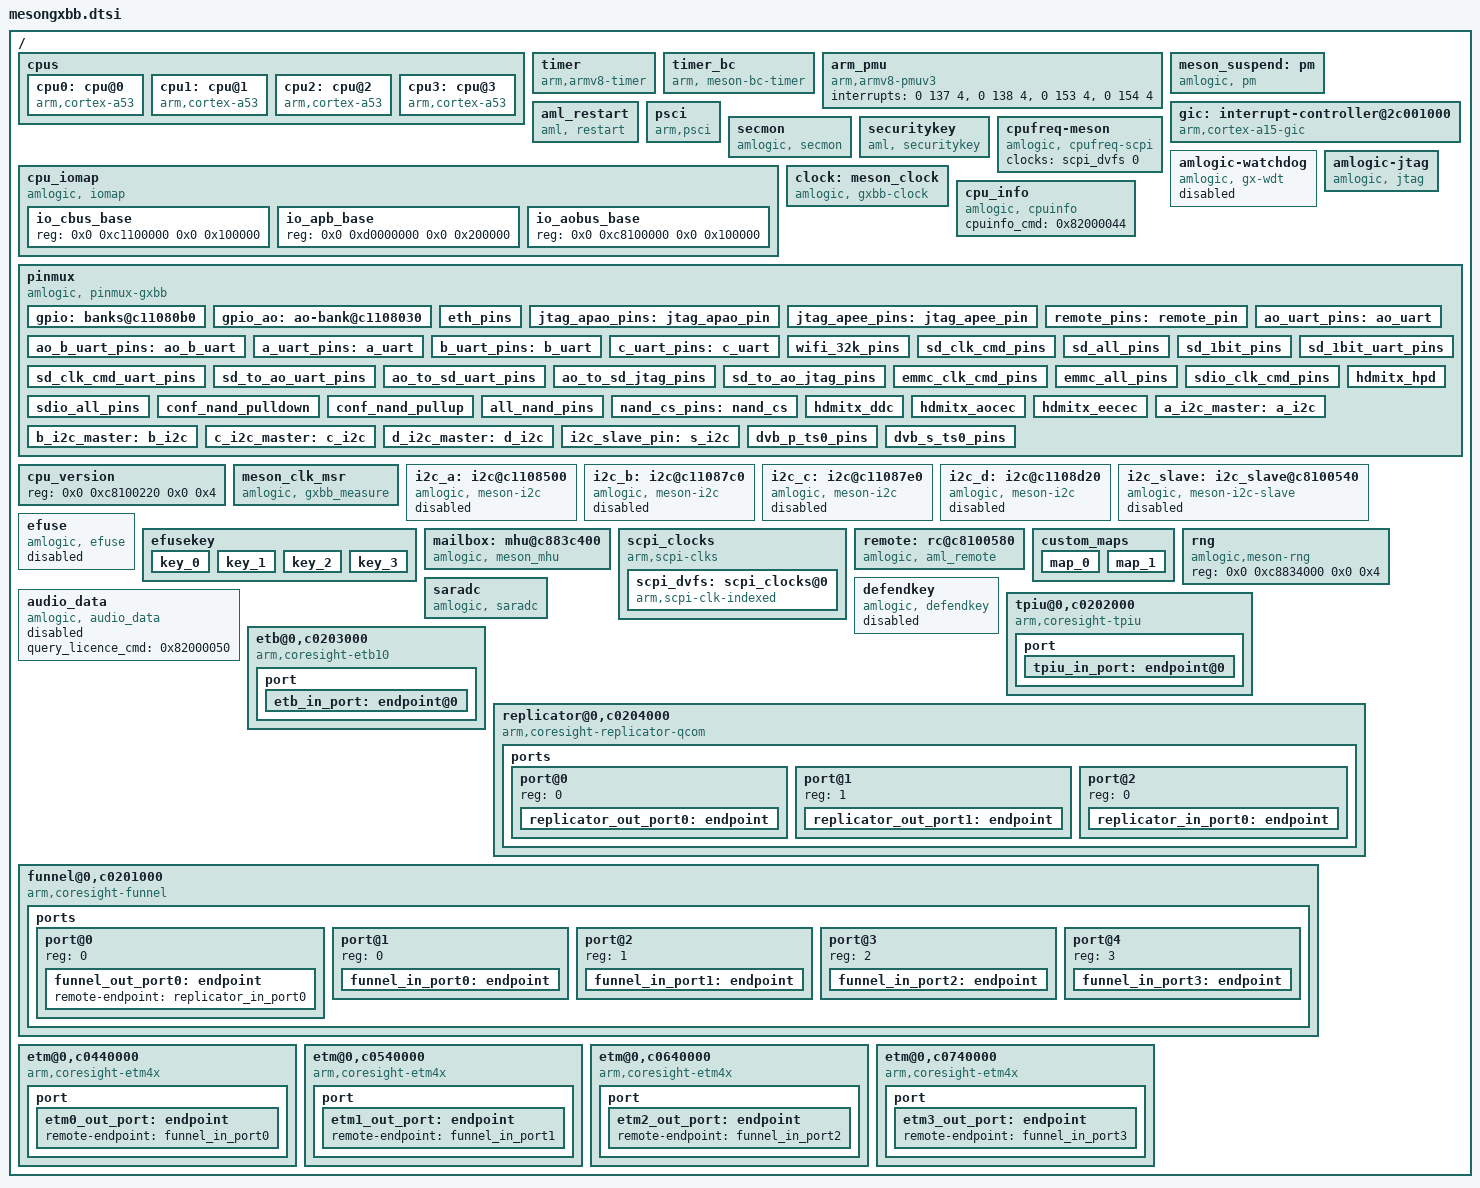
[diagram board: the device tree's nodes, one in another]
#include <dt-bindings/clock/gxbb.h>
#include <dt-bindings/gpio/gxbb.h>
#include <dt-bindings/gpio/gpio.h>
#include <dt-bindings/reset/aml_gxbb.h>
#include <dt-bindings/thermal/thermal.h>
#include <dt-bindings/interrupt-controller/arm-gic.h>
#include <dt-bindings/input/input.h>
#include <dt-bindings/input/meson_rc.h>
#include "mesongxbb-gpu-mali450.dtsi"
/ {
	cpus:cpus {
		#address-cells = <2>;
		#size-cells = <0>;
		#cooling-cells = <2>; /* min followed by max */

		cpu0:cpu@0 {
			device_type = "cpu";
			compatible = "arm,cortex-a53","arm,armv8";
			reg = <0x0 0x0>;
			enable-method = "psci";
		};

		cpu1:cpu@1 {
			device_type = "cpu";
			compatible = "arm,cortex-a53","arm,armv8";
			reg = <0x0 0x1>;
			enable-method = "psci";
		};
		cpu2:cpu@2 {
			device_type = "cpu";
			compatible = "arm,cortex-a53","arm,armv8";
			reg = <0x0 0x2>;
			enable-method = "psci";
		};

		cpu3:cpu@3 {
			device_type = "cpu";
			compatible = "arm,cortex-a53","arm,armv8";
			reg = <0x0 0x3>;
			enable-method = "psci";
		};

	};

	timer {
		compatible = "arm,armv8-timer";
		interrupts = <GIC_PPI 13 0xff01>,
				<GIC_PPI 14 0xff01>,
			        <GIC_PPI 11 0xff01>,
			        <GIC_PPI 10 0xff01>;
	};
	timer_bc {
		compatible = "arm, meson-bc-timer";
		reg=   <0x0 0xc1109990 0x0 0x4 0x0 0xc1109994 0x0 0x4>;
		timer_name = "Meson TimerF";
		clockevent-rating=<300>;
		clockevent-shift=<20>;
		clockevent-features=<0x03>;
		interrupts = <0 60 1>;
		bit_enable=<16>;
		bit_mode=<12>;
		bit_resolution=<0>;
	};
	arm_pmu {
		compatible = "arm,armv8-pmuv3";
		interrupts = <0 137 4>,
			     <0 138 4>,
			     <0 153 4>,
			     <0 154 4>;
	};
	meson_suspend:pm{
	           compatible = "amlogic, pm";
	           device_name = "aml_pm";
	           gxbaby-suspend;
	           reg = <0x0 0xc81000a8 0x0 0x4
				0x0 0xc810023c 0x0 0x4>;
	};

	gic: interrupt-controller@2c001000 {
		compatible = "arm,cortex-a15-gic", "arm,cortex-a9-gic";
		#interrupt-cells = <3>;
		#address-cells = <0>;
		interrupt-controller;
		reg = <0x0 0xc4301000 0 0x1000>,
		      <0x0 0xc4302000 0 0x0100>;
		interrupts = <GIC_PPI 9 0xf04>;
	};

	aml_restart{
		compatible = "aml, restart";
		sys_reset = <0x84000009>;
		sys_poweroff = <0x84000008>;
	};



	psci {
		compatible = "arm,psci";
		method = "smc";
		cpu_suspend = <0xC4000001>;
		cpu_off = <0x84000002>;
		cpu_on = <0xC4000003>;
		migrate = <0xC4000005>;
	};
	secmon {
		compatible = "amlogic, secmon";
		memory-region = <&secmon_reserved>;
		in_base_func = <0x82000020>;
		out_base_func = <0x82000021>;
	};
	securitykey {
		compatible = "aml, securitykey";
		storage_query = <0x82000060>;
		storage_read = <0x82000061>;
		storage_write = <0x82000062>;
		storage_tell = <0x82000063>;
		storage_verify = <0x82000064>;
		storage_status = <0x82000065>;
		storage_list = <0x82000067>;
		storage_remove = <0x82000068>;
		storage_in_func = <0x82000023>;
		storage_out_func = <0x82000024>;
		storage_block_func = <0x82000025>;
		storage_size_func = <0x82000027>;
		storage_set_enctype = <0x8200006A>;
		storage_get_enctype = <0x8200006B>;
		storage_version = <0x8200006C>;
	};
	cpu_iomap{
		compatible = "amlogic, iomap";
		#address-cells=<2>;
		#size-cells=<2>;
		ranges;
		io_cbus_base{
			reg = <0x0 0xc1100000 0x0 0x100000>;
		};
		io_apb_base{
			reg = <0x0 0xd0000000 0x0 0x200000>;
		};
		io_aobus_base{
			reg = <0x0 0xc8100000 0x0 0x100000>;
		};
	};
	cpufreq-meson {
		compatible = "amlogic, cpufreq-scpi";
		status = "okay";
		clocks = <&scpi_dvfs 0>;
		clock-names = "cpu_clk";
        };

	amlogic-watchdog{
		compatible = "amlogic, gx-wdt";
		status = "disable";
		default_timeout=<10>;
		reset_watchdog_method=<1>;//0:sysfs,1:kernel
		reset_watchdog_time=<2>;
		shutdown_timeout=<10>;
		firmware_timeout=<6>;
		suspend_timeout=<6>;
		reg = <0x0 0xc11098d0 0x0 0x10>;
		clocks = <&clock CLK_XTAL>;
	};
	amlogic-jtag {
		compatible = "amlogic, jtag";
		status = "okay";
		pinctrl-names = "jtag_apao_pins", "jtag_apee_pins";
		pinctrl-0 = <&jtag_apao_pins>;
		pinctrl-1 = <&jtag_apee_pins>;
	};
	clock: meson_clock {
		compatible = "amlogic, gxbb-clock";
		reg = <0x0 0xc883c000 0x0 0x1000>,   /* HIU BUS*/
		          <0x0 0xc8100000 0x0 0x1000>;   //AOBUS
		#clock-cells = <1>;
		#reset-cells = <1>;
		sys_max = <1536000000>;
	};
	cpu_info{
		compatible = "amlogic, cpuinfo";
		cpuinfo_cmd = <0x82000044>;
	};
	pinmux: pinmux{
		compatible = "amlogic, pinmux-gxbb";
		dev_name = "pinmux";
		#pinmux-cells=<2>;
		#address-cells = <2>;
		#size-cells = <2>;
		reg = <0x0 0xc1109880 0x0 0x10>;
		ranges;
		gpio: banks@c11080b0 {
			reg = <0x0 0xc88344b0 0x0 0x28>,
			<0x0 0xc88344e8 0x0 0x14>,
			<0x0 0xc8834520 0x0 0x14>,
			<0x0 0xc8834430 0x0 0x40>;
			reg-names = "mux", "pull", "pull-enable", "gpio";
			gpio-controller;
			#gpio-cells = <2>;
		};
		gpio_ao: ao-bank@c1108030 {
			reg = <0x0 0xc8100014 0x0 0x8>,
			<0x0 0xc810002c 0x0 0x4>,
			<0x0 0xc8100024 0x0 0x8>;
			reg-names = "mux", "pull", "gpio";
			gpio-controller;
			#gpio-cells = <2>;
		};
		eth_pins:eth_pins{
                        amlogic,setmask =<6 0x3fff>;
                        amlogic,clrmask =<6 0xc000>,
                                         <5 0x3c0000f0>,
                                         <4  0x300>;
                        amlogic,pins="GPIOZ_0","GPIOZ_1","GPIOZ_2","GPIOZ_3",
                                "GPIOZ_4","GPIOZ_5","GPIOZ_6","GPIOZ_7",
                                "GPIOZ_8","GPIOZ_9","GPIOZ_10","GPIOZ_11",
                                "GPIOZ_12","GPIOZ_13","GPIOZ_15";
                };
		jtag_apao_pins:jtag_apao_pin{
			amlogic,clrmask = <AO 0x78000000>;
			amlogic,pins = "GPIOAO_8","GPIOAO_9","GPIOAO_10","GPIOAO_11";
		};
		jtag_apee_pins:jtag_apee_pin{
			amlogic,clrmask = <2 0xcc00>;
			amlogic,pins = "CARD_0","CARD_1","CARD_2","CARD_3";
		};
		remote_pins:remote_pin{
			amlogic,setmask = <AO 0x1>;
			amlogic,pins = "GPIOAO_7";
		};
		ao_uart_pins:ao_uart{
			amlogic,setmask=<AO 0x1800>;
			amlogic,pins="GPIOAO_0", "GPIOAO_1";
		};
		ao_b_uart_pins:ao_b_uart{
			amlogic,setmask=<AO 0x1800000>;
			amlogic,pins="GPIOAO_4", "GPIOAO_5";
		};
		a_uart_pins:a_uart{
			amlogic,setmask=<4 0x3c00>;
			amlogic,pins="GPIOX_12", "GPIOX_13", "GPIOX_14", "GPIOX_15";
		};
		b_uart_pins:b_uart{
			amlogic,setmask=<2 0x30000000>;
			amlogic,pins="GPIODV_24", "GPIODV_25";
		};
		c_uart_pins:c_uart{
			amlogic,setmask=<1 0xc0000>;
			amlogic,pins="GPIOY_13", "GPIOY_14";
		};
		wifi_32k_pins:wifi_32k_pins{
			amlogic,setmask=<2 0x40000000>;
			amlogic,clrmask=<2 0x400000
												3 0x8000>;
			amlogic,pins="GPIOX_19";
		};
		sd_clk_cmd_pins:sd_clk_cmd_pins{
		    amlogic,setmask=<2 0x00000c00>,
												<AO 0x00001800>;
		    amlogic,pins = "CARD_2","CARD_3"; /* CARD_2:CLK, CARD_3:CMD */
		    amlogic,enable-output=<1>; /* 0:output, 1:input */
		    amlogic,pullup=<1>;
		    amlogic,pullupen=<1>;
		};
		sd_all_pins:sd_all_pins{
		    amlogic,setmask=<2 0x0000fc00>,
												<AO 0x00001800>;
		    amlogic,pins="CARD_0","CARD_1","CARD_2","CARD_3","CARD_4","CARD_5";
		    amlogic,enable-output=<1>; /* 0:output, 1:input */
		    amlogic,pullup=<1>;
		    amlogic,pullupen=<1>;
		};
		sd_1bit_pins:sd_1bit_pins{
			amlogic,setmask=<2 0x00008c00>,
												<AO 0x00001800>;
			amlogic,pins = "CARD_1","CARD_2","CARD_3";
			amlogic,enable-output=<1>; /* 0:output, 1:input */
			amlogic,pullup=<1>;
			amlogic,pullupen=<1>;
		};
		sd_clk_cmd_uart_pins:sd_clk_cmd_uart_pins{
		    amlogic,setmask=<2 0x00000c00>,
										<8 0x00000600>;
		    amlogic,pins = "CARD_2","CARD_3"; /* CARD_2:CLK, CARD_3:CMD */
		    amlogic,enable-output=<1>; /* 0:output, 1:input */
		    amlogic,pullup=<1>;
		    amlogic,pullupen=<1>;
		};
		sd_1bit_uart_pins:sd_1bit_uart_pins{
			amlogic,setmask=<2 0x00008c00>,
					<8 0x00000600>;
			amlogic,pins = "CARD_1","CARD_2","CARD_3";
			amlogic,enable-output=<1>; /* 0:output, 1:input */
			amlogic,pullup=<1>;
			amlogic,pullupen=<1>;
		};
		sd_to_ao_uart_pins:sd_to_ao_uart_pins{
			amlogic,setmask=<AO 0x00001800>;
			amlogic,clrmask=<8 0x00000600>;
			amlogic,pins = "GPIOAO_0","GPIOAO_1";
			amlogic,enable-output=<1>; /* 0:output, 1:input */
			amlogic,pullup=<1>;
			amlogic,pullupen=<1>;
		};
		ao_to_sd_uart_pins:ao_to_sd_uart_pins{
			amlogic,setmask=<8 0x00000600>;
			amlogic,clrmask=<AO 0x00001800>,
					<2 0x00003000>;
			amlogic,pins = "CARD_4","CARD_5";
			amlogic,enable-output=<1>; /* 0:output, 1:input */
			amlogic,pullup=<1>;
			amlogic,pullupen=<1>;
		};
		ao_to_sd_jtag_pins:ao_to_sd_jtag_pins{
			amlogic,setmask=<8 0x00000600>;
			amlogic,clrmask=<2 0x0000CC00>,
					<AO 0x00001800>;
			amlogic,pins = "CARD_4","CARD_5";
			amlogic,enable-output=<1>; /* 0:output, 1:input */
			amlogic,pullup=<1>;
			amlogic,pullupen=<1>;
		};
		sd_to_ao_jtag_pins:sd_to_ao_jtag_pins{
			amlogic,setmask=<AO 0x00001800>;
			amlogic,clrmask=<8 0x00000600>,
					<2 0x0000CC00>;
			amlogic,pins = "GPIOAO_0","GPIOAO_1";
			amlogic,enable-output=<1>; /* 0:output, 1:input */
			amlogic,pullup=<1>;
			amlogic,pullupen=<1>;
		};


		emmc_clk_cmd_pins:emmc_clk_cmd_pins{
		    amlogic,setmask=<4 0xc00c0000>;
		    amlogic,pins = "BOOT_8","BOOT_10"; /** BOOT_10:CMD, BOOT_8:CLK */
		    amlogic,enable-output=<1>; /** 0:output, 1:input */
		    amlogic,pullup=<1>;
		    amlogic,pullupen=<1>;
		};
		emmc_all_pins:emmc_all_pins{
		    amlogic,setmask=<4 0xc00c0000>;         /*sdhc c*/
		    amlogic,pins = "BOOT_0","BOOT_1","BOOT_2","BOOT_3","BOOT_4",
						"BOOT_5","BOOT_6","BOOT_7","BOOT_8","BOOT_10";
		    amlogic,enable-output=<1>; /** 0:output, 1:input */
		    amlogic,pullup=<1>;
		    amlogic,pullupen=<1>;
		};
		sdio_clk_cmd_pins:sdio_clk_cmd_pins{
		    amlogic,setmask=<8 0x00000003>;
		    amlogic,pins = "GPIOX_4","GPIOX_5"; /** GPIOX_5:CMD, GPIOX_4:CLK */
		    amlogic,enable-output=<1>; /** 0:output, 1:input */
		    amlogic,pullup=<1>;
		    amlogic,pullupen=<1>;
		};
		sdio_all_pins:sdio_all_pins{
		    amlogic,setmask=<8 0x0000003f>;
		    amlogic,pins = "GPIOX_0","GPIOX_1","GPIOX_2","GPIOX_3","GPIOX_4","GPIOX_5";
		    amlogic,enable-output=<1>; /** 0:output, 1:input */
		    amlogic,pullup=<1>;
		    amlogic,pullupen=<1>;
		};
		/*cam_gpio_b: cam_gpio_b{
				amlogic,setmask=<5 0xf0>;
				amlogic,clrmask=<4 0x300
						5 0xc000000
						6 0x1ff3>;
				amlogic,pins = "GPIOZ_0","GPIOZ_1","GPIOZ_3","GPIOZ_4","GPIOZ_5","GPIOZ_6","GPIOZ_7","GPIOZ_8","GPIOZ_9","GPIOZ_10","GPIOZ_11";
		};
		cam_gpio_a: cam_gpio_a{
				amlogic,setmask=<2 0x3f0000>;
				amlogic,clrmask=<1 0x7030ff
						3 0x37>;
				amlogic,pins = "GPIOY_1","GPIOY_0","GPIOY_2","GPIOY_15","GPIOY_16",
					"GPIOY_3","GPIOY_4","GPIOY_5","GPIOY_6",
					"GPIOY_7","GPIOY_8","GPIOY_9","GPIOY_10";
		};*/
		conf_nand_pulldown: conf_nand_pulldown{
			amlogic,pins = "BOOT_0","BOOT_1","BOOT_2","BOOT_3","BOOT_4",
						"BOOT_5","BOOT_6","BOOT_7","BOOT_15";
			amlogic,pullup=<0>;
			amlogic,pullupen=<1>;
		};
		conf_nand_pullup: conf_nand_pullup{
			amlogic,pins = "BOOT_8", "BOOT_10";
			amlogic,pullup=<1>;
			amlogic,pullupen=<1>;
		};
		all_nand_pins: all_nand_pins{
			amlogic,setmask=<4 0x7ff00000>;
			amlogic,clrmask=<0 0x80000
							4 0x800c0000
							5 0xf>;
			amlogic,pins = "BOOT_0","BOOT_1","BOOT_2","BOOT_3","BOOT_4",
						"BOOT_5","BOOT_6","BOOT_7","BOOT_8","BOOT_9",
						"BOOT_10","BOOT_11","BOOT_12","BOOT_13",
						"BOOT_14","BOOT_15","BOOT_16","BOOT_17";
			amlogic,enable-output=<1>;
		};
		nand_cs_pins: nand_cs{
			amlogic,setmask=<4 0xc000000>;
			amlogic,clrmask=<4 0x40000>;
			amlogic,pins = "BOOT_8","BOOT_9";
		};
		hdmitx_hpd: hdmitx_hpd {
			amlogic,setmask=<1 0x04000000>;
			amlogic,pins="GPIOH_0";
		};
		hdmitx_ddc: hdmitx_ddc {
			amlogic,setmask=<1 0x03000000>;
			amlogic,pins="GPIOH_1", "GPIOH_2";
		};
		hdmitx_aocec: hdmitx_aocec {
			amlogic,setmask=<AO  0x00008000>;
			amlogic,clrmask=<AO  0x00024000
					 AO2 0x00000001>;
			amlogic,pins="GPIOAO_12";
		};
		hdmitx_eecec: hdmitx_eecec {
			amlogic,setmask=<AO  0x00004000>;
			amlogic,clrmask=<AO  0x00028000
					 AO2 0x00000001>;
			amlogic,pins="GPIOAO_12";
		};

		/*p200 i2c-A multiplex with usb PWR*/
		a_i2c_master:a_i2c{
			amlogic,setmask=<7 0xc000000>;
			amlogic,clrmask=<0 0x18c0 2 0x30000000 5 0x1800>;
			amlogic,pins="GPIODV_24","GPIODV_25";
		};
		b_i2c_master:b_i2c{
			amlogic,setmask=<7 0x3000000>;
			amlogic,clrmask=<0 0x600 2 0xc000000 5 0x700>;
			amlogic,pins="GPIODV_26","GPIODV_27";
		};
		c_i2c_master:c_i2c{
			amlogic,setmask=<7 0xc00000>;
			amlogic,clrmask=<3 0x700000>;
			amlogic,pins="GPIODV_28","GPIODV_29";
		};
		d_i2c_master:d_i2c{
			amlogic,setmask=<4 0xc>;
			amlogic,clrmask=<2 0x3000000 3 0x1000>;
			amlogic,pins="GPIOX_16","GPIOX_17";
		};
		i2c_slave_pin:s_i2c{
			amlogic,setmask=<AO 0x6>;
			amlogic,clrmask=<AO 0x1800060>;
			amlogic,pins="GPIOAO_4","GPIOAO_5";
		};
		dvb_p_ts0_pins: dvb_p_ts0_pins {
			amlogic,setmask = <3 0x37>;
			amlogic,clrmask = <2 0xf0000 1 0x30ff>;
			amlogic,pins = "GPIOY_0","GPIOY_1","GPIOY_2", "GPIOY_3","GPIOY_4","GPIOY_5","GPIOY_6","GPIOY_7","GPIOY_8","GPIOY_9","GPIOY_10";
		};
		dvb_s_ts0_pins: dvb_s_ts0_pins {
			amlogic,setmask = <3 0x17>;
			amlogic,clrmask = <2 0xf0000 1 0x7>;
			amlogic,pins = "GPIOY_0","GPIOY_1","GPIOY_2","GPIOY_3";
		};
	};
	cpu_version{
		reg=<0x0 0xc8100220 0x0 0x4>;
	};
	meson_clk_msr{
		compatible = "amlogic, gxbb_measure";
		reg = <0x0 0xc110875c 0x0 0x4
		       0x0 0xc1108764 0x0 0x4>;
	};

	i2c_a: i2c@c1108500{ /*I2C-A*/
		compatible = "amlogic, meson-i2c";
		dev_name = "i2c-A";
		status = "disabled";
		reg = <0x0 0xc1108500 0x0 0x20>;
		device_id = <1>;
		pinctrl-names="default";
		pinctrl-0=<&a_i2c_master>;/*p200 i2c-A multiplex with usb PWR*/
		#address-cells = <1>;
		#size-cells = <0>;
		use_pio = <0>;
		master_i2c_speed = <300000>;
		clocks = <&clock CLK_81>;
		clock-names = "clk_i2c";
		resets = <&clock GCLK_IDX_I2C>;
	};
	i2c_b: i2c@c11087c0{ /*I2C-B*/
		compatible = "amlogic, meson-i2c";
		dev_name = "i2c-B";
		status = "disabled";
		reg = <0x0 0xc11087c0 0x0 0x20>;
		device_id = <2>;
		pinctrl-names="default";
		pinctrl-0=<&b_i2c_master>;
		#address-cells = <1>;
		#size-cells = <0>;
		use_pio = <0>;
		master_i2c_speed = <300000>;
		clocks = <&clock CLK_81>;
		clock-names = "clk_i2c";
		resets = <&clock GCLK_IDX_I2C>;
	};
	i2c_c: i2c@c11087e0{ /*I2C-C*/
		compatible = "amlogic, meson-i2c";
		dev_name = "i2c-C";
		status = "disabled";
		reg = <0x0 0xc11087e0 0x0 0x20>;
		device_id = <3>;
		pinctrl-names="default";
		pinctrl-0=<&c_i2c_master>;
		#address-cells = <1>;
		#size-cells = <0>;
		use_pio = <0>;
		master_i2c_speed = <300000>;
		clocks = <&clock CLK_81>;
		clock-names = "clk_i2c";
		resets = <&clock GCLK_IDX_I2C>;
	};
	i2c_d: i2c@c1108d20{ /*I2C-D*/
		compatible = "amlogic, meson-i2c";
		dev_name = "i2c-D";
		status = "disabled";
		reg = <0x0 0xc1108d20 0x0 0x20>;
		device_id = <4>;
		pinctrl-names="default";
		pinctrl-0=<&d_i2c_master>;
		#address-cells = <1>;
		#size-cells = <0>;
		use_pio = <0>;
		master_i2c_speed = <300000>;
		clocks = <&clock CLK_81>;
		clock-names = "clk_i2c";
		resets = <&clock GCLK_IDX_I2C>;
	};
	i2c_slave:i2c_slave@c8100540{
		compatible = "amlogic, meson-i2c-slave";
		status = "disabled";
		reg = <0x0 0xc8100540 0x0 0x20>;
		interrupts = <0 194 1>;
		pinctrl-names="default";
		pinctrl-0=<&i2c_slave_pin>;

	};
	efuse: efuse{
		compatible = "amlogic, efuse";
		read_cmd = <0x82000030>;
		write_cmd = <0x82000031>;
		get_max_cmd = <0x82000033>;
		key = <&efusekey>;
		resets = <&clock GCLK_IDX_EFUSE>;
		reset-names = "efuse_clk";
		status = "disabled";
	};
	efusekey:efusekey{
		keynum = <4>;
		key0 = <&key_0>;
		key1 = <&key_1>;
		key2 = <&key_2>;
		key3 = <&key_3>;
		key_0:key_0{
			keyname = "mac";
			offset = <0>;
			size = <6>;
		};
		key_1:key_1{
			keyname = "mac_bt";
			offset = <6>;
			size = <6>;
		};
		key_2:key_2{
			keyname = "mac_wifi";
			offset = <12>;
			size = <6>;
		};
		key_3:key_3{
			keyname = "usid";
			offset = <18>;
			size = <16>;
		};
	};

	mailbox: mhu@c883c400 {
		compatible = "amlogic, meson_mhu";
		reg = <0x0 0xc883c400 0x0 0x4c>,   /* MHU registers */
		      <0x0 0xc8013000 0x0 0x800>;   /* Payload area */
		interrupts = <0 209 IRQ_TYPE_EDGE_RISING>,   /* low priority interrupt */
			     <0 210 IRQ_TYPE_EDGE_RISING>;   /* high priority interrupt */
		#mbox-cells = <1>;
		mbox-names = "cpu_to_scp_low", "cpu_to_scp_high";
		mboxes = <&mailbox 0 &mailbox 1>;
	};
	scpi_clocks {
		compatible = "arm,scpi-clks";

		scpi_dvfs: scpi_clocks@0 {
			compatible = "arm,scpi-clk-indexed";
			#clock-cells = <1>;
			clock-indices = <0>;
			clock-output-names = "vcpu";
		};

	};
	remote:rc@c8100580 {
		compatible = "amlogic, aml_remote";
		dev_name = "meson-remote";
		reg = <0x0 0xc8100580 0x00 0x11>;
		status = "ok";
		protocol = <REMOTE_TYPE_NEC>;
		interrupts = <0 196 1>;
		pinctrl-names = "default";
		pinctrl-0 = <&remote_pins>;
		map = <&custom_maps>;
		release_delay = <80>;
		max_frame_time = <200>; /*set software decoder max frame time*/
	};

	custom_maps:custom_maps {
		mapnum = <2>;
		map0 = <&map_0>;
		map1 = <&map_1>;
		map_0: map_0{
			mapname = "amlogic-remote-1";
			customcode = <0xfb04>;
			size  = <44>;   /*keymap size*/
			keymap = <REMOTE_KEY(0x47, KEY_0)
				REMOTE_KEY(0x13, KEY_1)
				REMOTE_KEY(0x10, KEY_2)
				REMOTE_KEY(0x11, KEY_3)
				REMOTE_KEY(0x0F, KEY_4)
				REMOTE_KEY(0x0C, KEY_5)
				REMOTE_KEY(0x0D, KEY_6)
				REMOTE_KEY(0x0B, KEY_7)
				REMOTE_KEY(0x08, KEY_8)
				REMOTE_KEY(0x09, KEY_9)
				REMOTE_KEY(0x5C, KEY_RIGHTCTRL)
				REMOTE_KEY(0x51, KEY_F7)
				REMOTE_KEY(0x49, KEY_BACKSPACE)
				REMOTE_KEY(0x06, KEY_PROPS)
				REMOTE_KEY(0x14, KEY_UNDO)
				REMOTE_KEY(0x44, KEY_UP)
				REMOTE_KEY(0x1D, KEY_DOWN)
				REMOTE_KEY(0x1C, KEY_LEFT)
				REMOTE_KEY(0x48, KEY_RIGHT)
				REMOTE_KEY(0x53, KEY_LEFTMETA)
				REMOTE_KEY(0x45, KEY_PAGEUP)
				REMOTE_KEY(0x19, KEY_PAGEDOWN)
				REMOTE_KEY(0x16, KEY_HOME)//
				REMOTE_KEY(0x52, KEY_PAUSE)
				REMOTE_KEY(0x05, KEY_HANGEUL)
				REMOTE_KEY(0x59, KEY_HANJA)
				REMOTE_KEY(0x1b, KEY_SCALE)
				REMOTE_KEY(0x04, KEY_KPCOMMA)
				REMOTE_KEY(0x1A, KEY_POWER)
				REMOTE_KEY(0x0A, KEY_TAB)
				REMOTE_KEY(0x0e, KEY_MUTE)
				REMOTE_KEY(0x15, KEY_F5)
				REMOTE_KEY(0x1F, KEY_HOME)
				REMOTE_KEY(0x1e, KEY_FRONT)
				REMOTE_KEY(0x07, KEY_COPY)
				REMOTE_KEY(0x12, KEY_OPEN)
				REMOTE_KEY(0x54, KEY_PASTE)
				REMOTE_KEY(0x02, KEY_FIND)
				REMOTE_KEY(0x4f, KEY_A)
				REMOTE_KEY(0x42, KEY_B)
				REMOTE_KEY(0x5d, KEY_C)
				REMOTE_KEY(0x4c, KEY_D)
				REMOTE_KEY(0x58, KEY_CUT)
				REMOTE_KEY(0x55, KEY_CALC)>;
		};
		map_1: map_1{
			mapname = "amlogic-remote-2";
			customcode = <0xfe01>;
			size  = <53>;
			keymap = <REMOTE_KEY(0x01, KEY_1)
				REMOTE_KEY(0x02, KEY_2)
				REMOTE_KEY(0x03, KEY_3)
				REMOTE_KEY(0x04, KEY_4)
				REMOTE_KEY(0x05, KEY_5)
				REMOTE_KEY(0x06, KEY_6)
				REMOTE_KEY(0x07, KEY_7)
				REMOTE_KEY(0x08, KEY_8)
				REMOTE_KEY(0x09, KEY_9)
				REMOTE_KEY(0x0a, KEY_0)
				REMOTE_KEY(0x1F, KEY_FN_F1)
				REMOTE_KEY(0x15, KEY_MENU)
				REMOTE_KEY(0x16, KEY_TAB)
				REMOTE_KEY(0x0c, KEY_CHANNELUP)
				REMOTE_KEY(0x0d, KEY_CHANNELDOWN)
				REMOTE_KEY(0x0e, KEY_VOLUMEUP)
				REMOTE_KEY(0x0f, KEY_VOLUMEDOWN)
				REMOTE_KEY(0x11, KEY_HOME)
				REMOTE_KEY(0x1c, KEY_RIGHT)
				REMOTE_KEY(0x1b, KEY_LEFT)
				REMOTE_KEY(0x19, KEY_UP)
				REMOTE_KEY(0x1a, KEY_DOWN)
				REMOTE_KEY(0x1d, KEY_ENTER)
				REMOTE_KEY(0x17, KEY_MUTE)
				REMOTE_KEY(0x49, KEY_FINANCE)
				REMOTE_KEY(0x43, KEY_BACK)
				REMOTE_KEY(0x12, KEY_FN_F4)
				REMOTE_KEY(0x14, KEY_FN_F5)
				REMOTE_KEY(0x18, KEY_FN_F6)
				REMOTE_KEY(0x59, KEY_INFO)
				REMOTE_KEY(0x5a, KEY_STOPCD)
				REMOTE_KEY(0x10, KEY_POWER)
				REMOTE_KEY(0x42, KEY_PREVIOUSSONG)
				REMOTE_KEY(0x44, KEY_NEXTSONG)
				REMOTE_KEY(0x1e, KEY_REWIND)
				REMOTE_KEY(0x4b, KEY_FASTFORWARD)
				REMOTE_KEY(0x58, KEY_PLAYPAUSE)
				REMOTE_KEY(0x46, KEY_PROPS)
				REMOTE_KEY(0x40, KEY_UNDO)
				REMOTE_KEY(0x38, KEY_SCROLLLOCK)
				REMOTE_KEY(0x57, KEY_FN)
				REMOTE_KEY(0x5b, KEY_FN_ESC)
				REMOTE_KEY(0x54, KEY_RED)
				REMOTE_KEY(0x4c, KEY_GREEN)
				REMOTE_KEY(0x4e, KEY_YELLOW)
				REMOTE_KEY(0x55, KEY_BLUE)
				REMOTE_KEY(0x53, KEY_BLUETOOTH)
				REMOTE_KEY(0x52, KEY_WLAN)
				REMOTE_KEY(0x39, KEY_CAMERA)
				REMOTE_KEY(0x41, KEY_SOUND)
				REMOTE_KEY(0x0b, KEY_QUESTION)
				REMOTE_KEY(0x00, KEY_CHAT)
				REMOTE_KEY(0x13, KEY_SEARCH)>;
		};
 	};

	rng {
		compatible = "amlogic,meson-rng";
		reg = <0x0 0xc8834000 0x0 0x4>;
	};

	audio_data:audio_data {
		compatible = "amlogic, audio_data";
		query_licence_cmd = <0x82000050>;
		status = "disabled";
	};

	saradc: saradc {
		compatible = "amlogic, saradc";
		status = "okay";
		interrupts = <0 9 1>;
		interrupt-names = "saradc_int";
		clocks = <&clock CLK_XTAL>;
		clock-names = "saradc_clk";
		resets = <&clock GCLK_IDX_SARADC>;
		reg = <0x0 0xc1108680 0x0 0x30
					 0x0 0xc883c3d8 0x0 0x08>;
	};

	defendkey: defendkey {
		compatible = "amlogic, defendkey";
		reg = <0x0 0xc8834500 0x0 0x4>; /*RAND64_ADDR0*/
		mem_size = <0x0 0x100000>;
		status = "disabled";
	};

	tpiu@0,c0202000 {
		compatible = "arm,coresight-tpiu", "arm,primecell";
		reg = <0 0xc0202000 0 0x1000>;

		clocks = <&clock CLK_APB_P>;
		clock-names = "apb_pclk";
		port {
			tpiu_in_port: endpoint@0 {
				slave-mode;
				remote-endpoint = <&replicator_out_port0>;
			};
		};
	};

	etb@0,c0203000 {
		compatible = "arm,coresight-etb10", "arm,primecell";
		reg = <0 0xc0203000 0 0x1000>;

		clocks = <&clock CLK_APB_P>;
		clock-names = "apb_pclk";
		port {
			etb_in_port: endpoint@0 {
				slave-mode;
				remote-endpoint = <&replicator_out_port1>;
			};
		};
	};

	replicator@0,c0204000 {
		compatible = "arm,coresight-replicator-qcom", "arm,primecell";
		reg = <0 0xc0204000 0 0x1000>;

		clocks = <&clock CLK_APB_P>;
		clock-names = "apb_pclk";
		ports {
			#address-cells = <1>;
			#size-cells = <0>;

			/* replicator output ports */
			port@0 {
				#address-cells = <1>;
				#size-cells = <0>;
				reg = <0>;
				replicator_out_port0: endpoint {
					reg = <0>;
					remote-endpoint = <&tpiu_in_port>;
				};
			};

			port@1 {
				#address-cells = <1>;
				#size-cells = <0>;
				reg = <1>;
				replicator_out_port1: endpoint {
					reg = <1>;
					remote-endpoint = <&etb_in_port>;
				};
			};

			/* replicator input port */
			port@2 {
				reg = <0>;
				replicator_in_port0: endpoint {
					slave-mode;
					remote-endpoint = <&funnel_out_port0>;
				};
			};
		};
	};

	funnel@0,c0201000 {
		compatible = "arm,coresight-funnel", "arm,primecell";
		reg = <0 0xc0201000 0 0x1000>;

		clocks = <&clock CLK_APB_P>;
		clock-names = "apb_pclk";
		ports {
			#address-cells = <1>;
			#size-cells = <0>;

			/* funnel output port */
			port@0 {
				reg = <0>;
				funnel_out_port0: endpoint {
					remote-endpoint = <&replicator_in_port0>;
				};
			};

			/* funnel input ports */
			port@1 {
				reg = <0>;
				funnel_in_port0: endpoint {
					slave-mode;
					remote-endpoint = <&etm0_out_port>;
				};
			};

			port@2 {
				reg = <1>;
				funnel_in_port1: endpoint {
					slave-mode;
					remote-endpoint = <&etm1_out_port>;
				};
			};

			port@3 {
				reg = <2>;
				funnel_in_port2: endpoint {
					slave-mode;
					remote-endpoint = <&etm2_out_port>;
				};
			};

			port@4 {
				reg = <3>;
				funnel_in_port3: endpoint {
					slave-mode;
					remote-endpoint = <&etm3_out_port>;
				};
			};
		};
	};

	etm@0,c0440000 {
		compatible = "arm,coresight-etm4x", "arm,primecell";
		reg = <0 0xc0440000 0 0x1000>;

		cpu = <&cpu0>;
		clocks = <&clock CLK_APB_P>;
		clock-names = "apb_pclk";
		port {
			etm0_out_port: endpoint {
				remote-endpoint = <&funnel_in_port0>;
			};
		};
	};

	etm@0,c0540000 {
		compatible = "arm,coresight-etm4x", "arm,primecell";
		reg = <0 0xc0540000 0 0x1000>;

		cpu = <&cpu1>;
		clocks = <&clock CLK_APB_P>;
		clock-names = "apb_pclk";
		port {
			etm1_out_port: endpoint {
				remote-endpoint = <&funnel_in_port1>;
			};
		};
	};

	etm@0,c0640000 {
		compatible = "arm,coresight-etm4x", "arm,primecell";
		reg = <0 0xc0640000 0 0x1000>;

		cpu = <&cpu2>;
		clocks = <&clock CLK_APB_P>;
		clock-names = "apb_pclk";
		port {
			etm2_out_port: endpoint {
				remote-endpoint = <&funnel_in_port2>;
			};
		};
	};

	etm@0,c0740000 {
		compatible = "arm,coresight-etm4x", "arm,primecell";
		reg = <0 0xc0740000 0 0x1000>;

		cpu = <&cpu3>;
		clocks = <&clock CLK_APB_P>;
		clock-names = "apb_pclk";
		port {
			etm3_out_port: endpoint {
				remote-endpoint = <&funnel_in_port3>;
			};
		};
	};


};/* end of / */
